# ATmega1284RFR2 register map
Vendor: Atmel; File version: 1.0
CPU: other r0p0, little endian, no MPU, no FPU, 4 interrupt priority bits
Registers are 8-bit, read-write, reset 0x0 unless marked. A register's access mark holds for its fields unless they carry their own. Offsets are from the block's base; [hi:lo] are bit positions; 'fields as' and 'values as' point back to an identical list.

## SPI — Serial Peripheral Interface
Base 0x0080004C
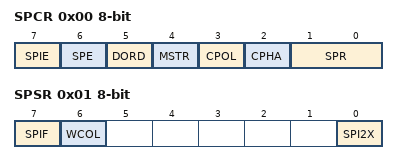
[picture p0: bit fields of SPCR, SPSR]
0x00 SPCR — SPI Control Register
  [7] SPIE — SPI Interrupt Enable
  [6] SPE — SPI Enable
  [5] DORD — Data Order
  [4] MSTR — Master/Slave Select
  [3] CPOL — Clock polarity
    0=RISING_LEADING_EDGE_FALLING_TRAILING_EDGE; 1=FALLING_LEADING_EGDE_RISING_TRAILING_EDGE (Falling (Leading Edge), Rising (Trailing Edge))
  [2] CPHA — Clock Phase
    0=SAMPLE_LEADING_EDGE_SETUP_TRAILING_EDGE; 1=SETUP_LEADING_EDGE_SAMPLE_TRAILING_EDGE
  [1:0] SPR — SPI Clock Rate Select 1 and 0
    0=FOSC_4_FOSC_2_SPI2X_0_1; 1=FOSC_16_FOSC_8_SPI2X_0_1; 2=FOSC_64_FOSC_32_SPI2X_0_1; 3=FOSC_128_FOSC_64_SPI2X_0_1
0x01 SPSR — SPI Status Register (read-only for debugger)
  [7] SPIF — SPI Interrupt Flag
  [6] WCOL — Write Collision Flag
  [0] SPI2X — Double SPI Speed Bit
0x02 SPDR — SPI Data Register (write-only for debugger)

## TC0 — Timer/Counter, 8-bit
Base 0x00800035
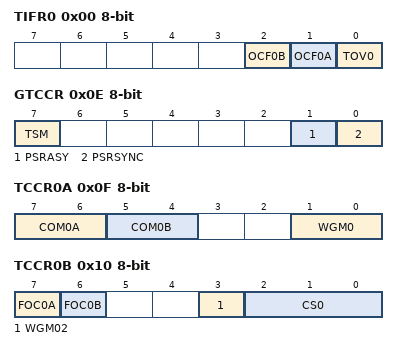
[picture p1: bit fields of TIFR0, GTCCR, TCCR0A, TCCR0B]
0x00 TIFR0 — Timer/Counter0 Interrupt Flag Register (read-only for debugger)
  [2] OCF0B — Timer/Counter0 Output Compare B Match Flag
  [1] OCF0A — Timer/Counter0 Output Compare A Match Flag
  [0] TOV0 — Timer/Counter0 Overflow Flag
0x0E GTCCR — General Timer/Counter Control Register
  [7] TSM — Timer/Counter Synchronization Mode
  [1] PSRASY — Prescaler Reset Timer/Counter2
  [0] PSRSYNC — Prescaler Reset for Synchronous Timer/Counters
0x0F TCCR0A — Timer/Counter0 Control Register A
  [7:6] COM0A — Compare Match Output A Mode
    0=NORMAL_PORT_OPERATION_OC0A_DISCONNECTED; 1=TOGGLE_OC0A_ON_COMPARE_MATCH; 2=CLEAR_OC0A_ON_COMPARE_MATCH; 3=SET_OC0A_ON_COMPARE_MATCH
  [5:4] COM0B — Compare Match Output B Mode
    0=NORMAL_PORT_OPERATION_OC0B_DISCONNECTED; 1=TOGGLE_OC0B_ON_COMPARE_MATCH; 2=CLEAR_OC0B_ON_COMPARE_MATCH; 3=SET_OC0B_ON_COMPARE_MATCH
  [1:0] WGM0 — Waveform Generation Mode
    0=NORMAL_MODE_OF_OPERATION; 1=PWM_PHASE_CORRECT_TOP_0XFF; 2=CTC_TOP_OCRA; 3=FAST_PWM_TOP_0XFF
0x10 TCCR0B — Timer/Counter0 Control Register B
  [7] FOC0A — Force Output Compare A
  [6] FOC0B — Force Output Compare B
  [3] WGM02
  [2:0] CS0 — Clock Select
    0=NO_CLOCK_SOURCE_TIMER_COUNTER0_STOPPED; 1=CLK_IO_1_NO_PRESCALING; 2=CLK_IO_8_FROM_PRESCALER; 3=CLK_IO_64_FROM_PRESCALER; 4=CLK_IO_256_FROM_PRESCALER; 5=CLK_IO_1024_FROM_PRESCALER; 6=EXTERNAL_CLOCK_SOURCE_ON_T0_PIN_CLOCK_ON_FALLING_EDGE; 7=EXTERNAL_CLOCK_SOURCE_ON_T0_PIN_CLOCK_ON_RISING_EDGE
0x11 TCNT0 — Timer/Counter0 Register
0x12 OCR0A — Timer/Counter0 Output Compare Register
0x13 OCR0B — Timer/Counter0 Output Compare Register B
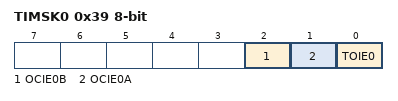
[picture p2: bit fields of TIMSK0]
0x39 TIMSK0 — Timer/Counter0 Interrupt Mask Register
  [2] OCIE0B — Timer/Counter0 Output Compare Match B Interrupt Enable
  [1] OCIE0A — Timer/Counter0 Output Compare Match A Interrupt Enable
  [0] TOIE0 — Timer/Counter0 Overflow Interrupt Enable

## TC1 — Timer/Counter, 16-bit
Base 0x00800036
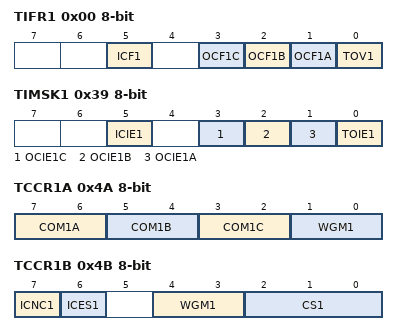
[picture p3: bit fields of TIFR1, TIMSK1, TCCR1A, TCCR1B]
0x00 TIFR1 — Timer/Counter1 Interrupt Flag Register (read-only for debugger)
  [5] ICF1 — Timer/Counter1 Input Capture Flag
  [3] OCF1C — Timer/Counter1 Output Compare C Match Flag
  [2] OCF1B — Timer/Counter1 Output Compare B Match Flag
  [1] OCF1A — Timer/Counter1 Output Compare A Match Flag
  [0] TOV1 — Timer/Counter1 Overflow Flag
0x39 TIMSK1 — Timer/Counter1 Interrupt Mask Register
  [5] ICIE1 — Timer/Counter1 Input Capture Interrupt Enable
  [3] OCIE1C — Timer/Counter1 Output Compare C Match Interrupt Enable
  [2] OCIE1B — Timer/Counter1 Output Compare B Match Interrupt Enable
  [1] OCIE1A — Timer/Counter1 Output Compare A Match Interrupt Enable
  [0] TOIE1 — Timer/Counter1 Overflow Interrupt Enable
0x4A TCCR1A — Timer/Counter1 Control Register A
  [7:6] COM1A — Compare Output Mode for Channel A
    0=NORMAL_PORT_OPERATION_OCNA_OCNB_OCNC_DISCONNECTED; 1=TOGGLE_OCNA_OCNB_OCNC_ON_COMPARE_MATCH; 2=CLEAR_OCNA_OCNB_OCNC_ON_COMPARE_MATCH_SET_OUTPUT_TO_LOW_LEVEL; 3=SET_OCNA_OCNB_OCNC_ON_COMPARE_MATCH_SET_OUTPUT_TO_HIGH_LEVEL
  [5:4] COM1B — Compare Output Mode for Channel B
    values as COM1A
  [3:2] COM1C — Compare Output Mode for Channel C
    values as COM1A
  [1:0] WGM1 — Waveform Generation Mode
    0=NORMAL_MODE_OF_OPERATION; 1=PWM_PHASE_CORRECT_8_BIT; 2=PWM_PHASE_CORRECT_9_BIT; 3=PWM_PHASE_CORRECT_10_BIT
0x4B TCCR1B — Timer/Counter1 Control Register B
  [7] ICNC1 — Input Capture 1 Noise Canceller
  [6] ICES1 — Input Capture 1 Edge Select
  [4:3] WGM1 — Waveform Generation Mode
    values as TCCR1A.WGM1
  [2:0] CS1 — Clock Select
    0=NO_CLOCK_SOURCE_TIMER_COUNTER_STOPPED; 1=CLK_IO_1_NO_PRESCALING; 2=CLK_IO_8_FROM_PRESCALER; 3=CLK_IO_64_FROM_PRESCALER; 4=CLK_IO_256_FROM_PRESCALER; 5=CLK_IO_1024_FROM_PRESCALER; 6=EXTERNAL_CLOCK_SOURCE_ON_TN_PIN_CLOCK_ON_FALLING_EDGE; 7=EXTERNAL_CLOCK_SOURCE_ON_TN_PIN_CLOCK_ON_RISING_EDGE
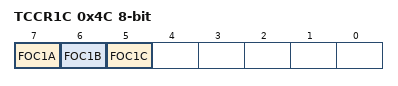
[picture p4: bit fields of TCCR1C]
0x4C TCCR1C — Timer/Counter1 Control Register C
  [7] FOC1A — Force Output Compare for Channel A
  [6] FOC1B — Force Output Compare for Channel B
  [5] FOC1C — Force Output Compare for Channel C
0x4E TCNT1 16-bit (reset mask 0xFF) — Timer/Counter1 Bytes
0x50 ICR1 16-bit (reset mask 0xFF) — Timer/Counter1 Input Capture Register Bytes
0x52 OCR1A 16-bit (reset mask 0xFF) — Timer/Counter1 Output Compare Register A Bytes
0x54 OCR1B 16-bit (reset mask 0xFF) — Timer/Counter1 Output Compare Register B Bytes
0x56 OCR1C 16-bit (reset mask 0xFF) — Timer/Counter1 Output Compare Register C Bytes
